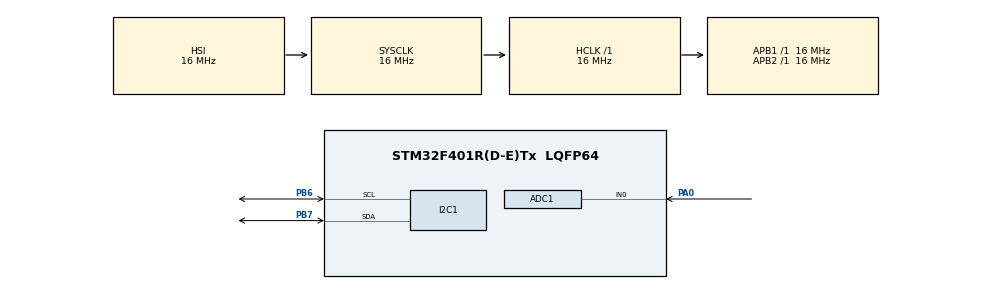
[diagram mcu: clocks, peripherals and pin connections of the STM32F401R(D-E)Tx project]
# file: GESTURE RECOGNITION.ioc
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ADC1.Channel-0\#ChannelRegularConversion=ADC_CHANNEL_0
ADC1.ContinuousConvMode=ENABLE
ADC1.NbrOfConversionFlag=1
ADC1.Rank-0\#ChannelRegularConversion=1
ADC1.SamplingTime-0\#ChannelRegularConversion=ADC_SAMPLETIME_3CYCLES
ADC1.master=1
Mcu.Family=STM32F4
Mcu.Name=STM32F401R(D-E)Tx
Mcu.Package=LQFP64
NVIC.PriorityGroup=NVIC_PRIORITYGROUP_4
PA0-WKUP.Signal=ADCx_IN0
PB6.Mode=I2C
PB6.Signal=I2C1_SCL
PB7.Mode=I2C
PB7.Signal=I2C1_SDA
PH0\ -\ OSC_IN.Mode=HSE-External-Oscillator
PH0\ -\ OSC_IN.Signal=RCC_OSC_IN
PH1\ -\ OSC_OUT.Mode=HSE-External-Oscillator
PH1\ -\ OSC_OUT.Signal=RCC_OSC_OUT
ProjectManager.HeapSize=0x200
ProjectManager.StackSize=0x400
ProjectManager.TargetToolchain=STM32CubeIDE
RCC.48MHZClocksFreq_Value=24000000
RCC.AHBFreq_Value=16000000
RCC.APB1Freq_Value=16000000
RCC.APB1TimFreq_Value=16000000
RCC.APB2Freq_Value=16000000
RCC.APB2TimFreq_Value=16000000
RCC.CortexFreq_Value=16000000
RCC.HCLKFreq_Value=16000000
RCC.HSE_VALUE=8000000
RCC.HSI_VALUE=16000000
RCC.LSE_VALUE=32768
RCC.PLLSourceVirtual=RCC_PLLSOURCE_HSE
RCC.SYSCLKFreq_VALUE=16000000
RCC.VCOOutputFreq_Value=96000000
SH.ADCx_IN0.0=ADC1_IN0,IN0
board=custom

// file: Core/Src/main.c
/* USER CODE BEGIN Header */
/**
  ******************************************************************************
  * @file           : main.c
  * @brief          : Main program body
  ******************************************************************************
  * @attention
  *
  * Copyright (c) 2024 STMicroelectronics.
  * All rights reserved.
  *
  * This software is licensed under terms that can be found in the LICENSE file
  * in the root directory of this software component.
  * If no LICENSE file comes with this software, it is provided AS-IS.
  *
  ******************************************************************************
  */
/* USER CODE END Header */
#include "main.h"
#include "i2c-lcd.h"

ADC_HandleTypeDef hadc1;

I2C_HandleTypeDef hi2c1;

void SystemClock_Config(void);
static void MX_GPIO_Init(void);
static void MX_ADC1_Init(void);
static void MX_I2C1_Init(void);

/* USER CODE BEGIN 0 */
uint16_t readValue;

/* USER CODE END 0 */
#define MPU6050_ADDR 0xD0

#define SMPLRT_DIV_REG 0x19
#define GYRO_CONFIG_REG 0x1B
#define ACCEL_CONFIG_REG 0x1C
#define ACCEL_XOUT_H_REG 0x3B
#define TEMP_OUT_H_REG 0x41
#define GYRO_XOUT_H_REG 0x43
#define PWR_MGMT_1_REG 0x6B
#define WHO_AM_I_REG 0x75

int16_t Accel_X_RAW = 0;
int16_t Accel_Y_RAW = 0;
int16_t Accel_Z_RAW = 0;

int16_t Gyro_X_RAW = 0;
int16_t Gyro_Y_RAW = 0;
int16_t Gyro_Z_RAW = 0;

float Ax, Ay, Az, Gx, Gy, Gz;

void MPU6050_Init (void)
{
	uint8_t check;
	uint8_t Data;

	// check device ID WHO_AM_I

	HAL_I2C_Mem_Read (&hi2c1, MPU6050_ADDR,WHO_AM_I_REG,1, &check, 1, 1000);

	if (check == 104)  // 0x68 will be returned by the sensor if everything goes well
	{
		// power management register 0X6B we should write all 0's to wake the sensor up
		Data = 0;
		HAL_I2C_Mem_Write(&hi2c1, MPU6050_ADDR, PWR_MGMT_1_REG, 1,&Data, 1, 1000);

		// Set DATA RATE of 1KHz by writing SMPLRT_DIV register
		Data = 0x07;
		HAL_I2C_Mem_Write(&hi2c1, MPU6050_ADDR, SMPLRT_DIV_REG, 1, &Data, 1, 1000);

		// Set accelerometer configuration in ACCEL_CONFIG Register
		// XA_ST=0,YA_ST=0,ZA_ST=0, FS_SEL=0 -> � 2g
		Data = 0x00;
		HAL_I2C_Mem_Write(&hi2c1, MPU6050_ADDR, ACCEL_CONFIG_REG, 1, &Data, 1, 1000);

		// Set Gyroscopic configuration in GYRO_CONFIG Register
		// XG_ST=0,YG_ST=0,ZG_ST=0, FS_SEL=0 -> � 250 �/s
		Data = 0x00;
		HAL_I2C_Mem_Write(&hi2c1, MPU6050_ADDR, GYRO_CONFIG_REG, 1, &Data, 1, 1000);
	}

}

void MPU6050_Read_Accel (void)
{
	uint8_t Rec_Data[6];

	// Read 6 BYTES of data starting from ACCEL_XOUT_H register

	HAL_I2C_Mem_Read (&hi2c1, MPU6050_ADDR, ACCEL_XOUT_H_REG, 1, Rec_Data, 6, 1000);

	Accel_X_RAW = (int16_t)(Rec_Data[0] << 8 | Rec_Data [1]);
	Accel_Y_RAW = (int16_t)(Rec_Data[2] << 8 | Rec_Data [3]);
	Accel_Z_RAW = (int16_t)(Rec_Data[4] << 8 | Rec_Data [5]);

	/*** convert the RAW values into acceleration in 'g'
	     we have to divide according to the Full scale value set in FS_SEL
	     I have configured FS_SEL = 0. So I am dividing by 16384.0
	     for more details check ACCEL_CONFIG Register              ****/

	Ax = Accel_X_RAW/16384.0;
	Ay = Accel_Y_RAW/16384.0;
	Az = Accel_Z_RAW/16384.0;
}

void MPU6050_Read_Gyro (void)
{
	uint8_t Rec_Data[6];

	// Read 6 BYTES of data starting from GYRO_XOUT_H register

	HAL_I2C_Mem_Read (&hi2c1, MPU6050_ADDR, GYRO_XOUT_H_REG, 1, Rec_Data, 6, 1000);

	Gyro_X_RAW = (int16_t)(Rec_Data[0] << 8 | Rec_Data [1]);
	Gyro_Y_RAW = (int16_t)(Rec_Data[2] << 8 | Rec_Data [3]);
	Gyro_Z_RAW = (int16_t)(Rec_Data[4] << 8 | Rec_Data [5]);

	/*** convert the RAW values into dps (�/s)
	     we have to divide according to the Full scale value set in FS_SEL
	     I have configured FS_SEL = 0. So I am dividing by 131.0
	     for more details check GYRO_CONFIG Register              ****/

	Gx = Gyro_X_RAW/131.0;
	Gy = Gyro_Y_RAW/131.0;
	Gz = Gyro_Z_RAW/131.0;
}

int main(void)
{
  /* USER CODE BEGIN 1 */
	char buf[4];

  /* USER CODE END 1 */

  /* MCU Configuration--------------------------------------------------------*/

  /* Reset of all peripherals, Initializes the Flash interface and the Systick. */
  HAL_Init();

  /* Configure the system clock */
  SystemClock_Config();

  /* Initialize all configured peripherals */
  MX_GPIO_Init();
  MX_ADC1_Init();
  MX_I2C1_Init();
  /* USER CODE BEGIN 2 */
  HAL_ADC_Start(&hadc1);

  /* USER CODE END 2 */
  lcd_init();

    MPU6050_Init();

    lcd_send_string ("initialized");

    HAL_Delay (1000);  // wait for 1 sec

    lcd_clear ();

    lcd_send_cmd (0x80|0x5A);
    lcd_send_string ("MPU6050");

  /* Infinite loop */
  while (1)
  {
	  HAL_ADC_PollForConversion(&hadc1,1000);
	  	readValue = HAL_ADC_GetValue(&hadc1);
	  	MPU6050_Read_Accel();
	  		  MPU6050_Read_Gyro();

	  		  // print the Acceleration and Gyro values on the LCD 20x4

	  		  lcd_send_cmd (0x80|0x00);  // goto 1,1
	  		  lcd_send_string ("Ax=");

	  		  lcd_send_string (buf);
	  		  lcd_send_string ("g ");

	  		  lcd_send_cmd (0x80|0x40);  // goto 2,1
	  		  lcd_send_string ("Ay=");

	  		  lcd_send_string (buf);
	  		  lcd_send_string ("g ");

	  		  lcd_send_cmd (0x80|0x14);  // goto 3,1
	  		  lcd_send_string ("Az=");

	  		  lcd_send_string (buf);
	  		  lcd_send_string ("g ");

	  		  lcd_send_cmd (0x80|0x0A);  // goto 1,11
	  		  lcd_send_string ("Gx=");

	  		  lcd_send_string (buf);

	  		  lcd_send_cmd (0x80|0x4A);  // goto 2,11
	  		  lcd_send_string ("Gy=");

	  		  lcd_send_string (buf);

	  		  lcd_send_cmd (0x80|0x1E);  // goto 3,11
	  		  lcd_send_string ("Gz=");

	  		  lcd_send_string (buf);
	  		 if((readValue>800)||(Ax>0.5)){lcd_send_cmd (0x80|0x4A);
	  		 lcd_send_string ("HELLO");}
	  		 else{lcd_send_cmd (0x80|0x1E);  // goto 3,11
	  		  lcd_send_string ("Gz=");}

  }
}

void SystemClock_Config(void)
{
  RCC_OscInitTypeDef RCC_OscInitStruct = {0};
  RCC_ClkInitTypeDef RCC_ClkInitStruct = {0};

  /** Configure the main internal regulator output voltage
  */
  __HAL_RCC_PWR_CLK_ENABLE();
  __HAL_PWR_VOLTAGESCALING_CONFIG(PWR_REGULATOR_VOLTAGE_SCALE2);

  /** Initializes the RCC Oscillators according to the specified parameters
  * in the RCC_OscInitTypeDef structure.
  */
  RCC_OscInitStruct.OscillatorType = RCC_OSCILLATORTYPE_HSI;
  RCC_OscInitStruct.HSIState = RCC_HSI_ON;
  RCC_OscInitStruct.HSICalibrationValue = RCC_HSICALIBRATION_DEFAULT;
  RCC_OscInitStruct.PLL.PLLState = RCC_PLL_NONE;
  if (HAL_RCC_OscConfig(&RCC_OscInitStruct) != HAL_OK)
  {
    Error_Handler();
  }

  /** Initializes the CPU, AHB and APB buses clocks
  */
  RCC_ClkInitStruct.ClockType = RCC_CLOCKTYPE_HCLK|RCC_CLOCKTYPE_SYSCLK
                              |RCC_CLOCKTYPE_PCLK1|RCC_CLOCKTYPE_PCLK2;
  RCC_ClkInitStruct.SYSCLKSource = RCC_SYSCLKSOURCE_HSI;
  RCC_ClkInitStruct.AHBCLKDivider = RCC_SYSCLK_DIV1;
  RCC_ClkInitStruct.APB1CLKDivider = RCC_HCLK_DIV1;
  RCC_ClkInitStruct.APB2CLKDivider = RCC_HCLK_DIV1;

  if (HAL_RCC_ClockConfig(&RCC_ClkInitStruct, FLASH_LATENCY_0) != HAL_OK)
  {
    Error_Handler();
  }
}

static void MX_ADC1_Init(void)
{

  ADC_ChannelConfTypeDef sConfig = {0};

  /** Configure the global features of the ADC (Clock, Resolution, Data Alignment and number of conversion)
  */
  hadc1.Instance = ADC1;
  hadc1.Init.ClockPrescaler = ADC_CLOCK_SYNC_PCLK_DIV2;
  hadc1.Init.Resolution = ADC_RESOLUTION_12B;
  hadc1.Init.ScanConvMode = DISABLE;
  hadc1.Init.ContinuousConvMode = ENABLE;
  hadc1.Init.DiscontinuousConvMode = DISABLE;
  hadc1.Init.ExternalTrigConvEdge = ADC_EXTERNALTRIGCONVEDGE_NONE;
  hadc1.Init.ExternalTrigConv = ADC_SOFTWARE_START;
  hadc1.Init.DataAlign = ADC_DATAALIGN_RIGHT;
  hadc1.Init.NbrOfConversion = 1;
  hadc1.Init.DMAContinuousRequests = DISABLE;
  hadc1.Init.EOCSelection = ADC_EOC_SINGLE_CONV;
  if (HAL_ADC_Init(&hadc1) != HAL_OK)
  {
    Error_Handler();
  }

  /** Configure for the selected ADC regular channel its corresponding rank in the sequencer and its sample time.
  */
  sConfig.Channel = ADC_CHANNEL_0;
  sConfig.Rank = 1;
  sConfig.SamplingTime = ADC_SAMPLETIME_3CYCLES;
  if (HAL_ADC_ConfigChannel(&hadc1, &sConfig) != HAL_OK)
  {
    Error_Handler();
  }

}

static void MX_I2C1_Init(void)
{

  hi2c1.Instance = I2C1;
  hi2c1.Init.ClockSpeed = 100000;
  hi2c1.Init.DutyCycle = I2C_DUTYCYCLE_2;
  hi2c1.Init.OwnAddress1 = 0;
  hi2c1.Init.AddressingMode = I2C_ADDRESSINGMODE_7BIT;
  hi2c1.Init.DualAddressMode = I2C_DUALADDRESS_DISABLE;
  hi2c1.Init.OwnAddress2 = 0;
  hi2c1.Init.GeneralCallMode = I2C_GENERALCALL_DISABLE;
  hi2c1.Init.NoStretchMode = I2C_NOSTRETCH_DISABLE;
  if (HAL_I2C_Init(&hi2c1) != HAL_OK)
  {
    Error_Handler();
  }

}

static void MX_GPIO_Init(void)
{

  /* GPIO Ports Clock Enable */
  __HAL_RCC_GPIOH_CLK_ENABLE();
  __HAL_RCC_GPIOA_CLK_ENABLE();
  __HAL_RCC_GPIOB_CLK_ENABLE();

}

void Error_Handler(void)
{
  __disable_irq();
  while (1)
  {
  }
}
